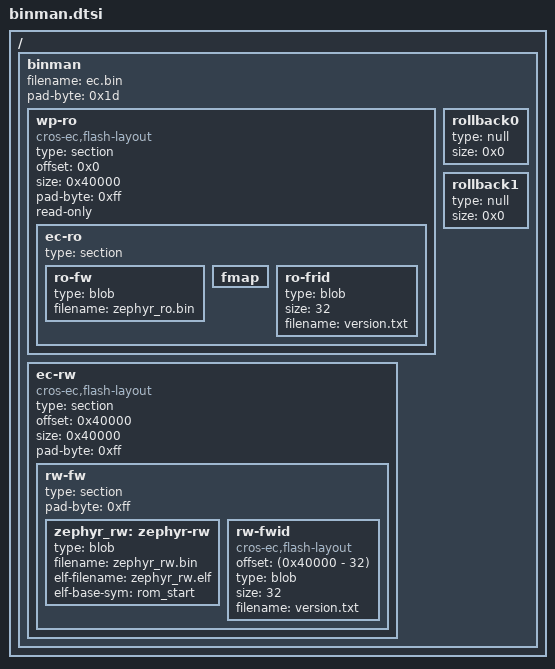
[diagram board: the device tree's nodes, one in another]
/* Copyright 2021 The ChromiumOS Authors
 * Use of this source code is governed by a BSD-style license that can be
 * found in the LICENSE file.
 */

/ {
	#address-cells = <1>;
	#size-cells = <1>;
	binman: binman {
		filename = "ec.bin";
		pad-byte = <0x1d>;
		wp-ro {
			compatible = "cros-ec,flash-layout";
			type = "section";
			offset = <0x0>;
			size = <0x40000>;
			pad-byte = <0xff>;
			read-only;
			ec-ro {
				type = "section";
				ro-fw {
					type = "blob";
					filename = "zephyr_ro.bin";
				};
				fmap {
				};
				ro-frid {
					type = "blob";
					size = <32>;
					filename = "version.txt";
				};
			};
		};

		rollback0 {
			type = "null";
			size = <0x0>;
		};

		rollback1 {
			type = "null";
			size = <0x0>;
		};

		ec-rw {
			compatible = "cros-ec,flash-layout";
			type = "section";
			offset = <0x40000>;
			size = <0x40000>;
			pad-byte = <0xff>;
			rw-fw {
				type = "section";
				pad-byte = <0xff>;
				zephyr_rw: zephyr-rw {
					type = "blob";
					filename = "zephyr_rw.bin";
					elf-filename = "zephyr_rw.elf";
					elf-base-sym = "rom_start";
				};
				rw-fwid {
					compatible = "cros-ec,flash-layout";
					/* Fix the location of the FWID to the
					 * last 32 bytes of the flash. This
					 * ensures the RW entries in the FMAP
					 * stored in the RO section of flash
					 * are always correct.
					 */
					offset = <(0x40000 - 32)>;
					type = "blob";
					size = <32>;
					filename = "version.txt";
				};
			};
		};
	};
};
